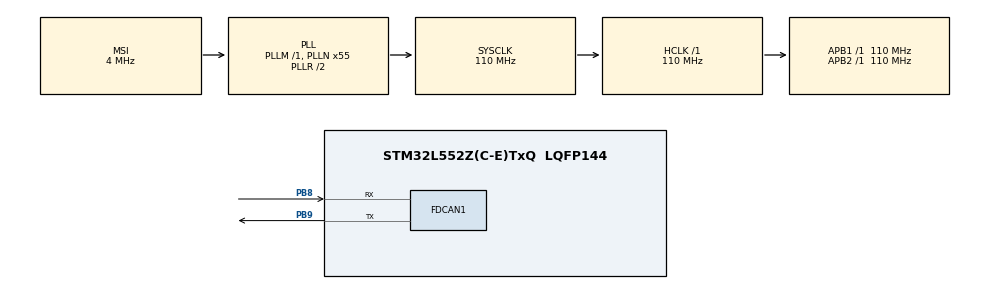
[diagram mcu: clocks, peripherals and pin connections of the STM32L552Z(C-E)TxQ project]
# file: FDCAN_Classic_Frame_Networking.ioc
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FDCAN1.AutoRetransmission=ENABLE
FDCAN1.CalculateBaudRateNominal=1374999
FDCAN1.CalculateTimeBitNominal=727
FDCAN1.CalculateTimeQuantumNominal=9.090909090909092
FDCAN1.ClockDivider=FDCAN_CLOCK_DIV1
FDCAN1.DataPrescaler=1
FDCAN1.DataSyncJumpWidth=4
FDCAN1.DataTimeSeg1=5
FDCAN1.DataTimeSeg2=4
FDCAN1.ExtFiltersNbr=0
FDCAN1.FrameFormat=FDCAN_FRAME_FD_BRS
FDCAN1.Mode=FDCAN_MODE_NORMAL
FDCAN1.NominalPrescaler=1
FDCAN1.NominalSyncJumpWidth=16
FDCAN1.NominalTimeSeg1=63
FDCAN1.NominalTimeSeg2=16
FDCAN1.ProtocolException=DISABLE
FDCAN1.StdFiltersNbr=1
FDCAN1.TransmitPause=ENABLE
FDCAN1.TxFifoQueueMode=FDCAN_TX_FIFO_OPERATION
Mcu.Family=STM32L5
Mcu.Name=STM32L552Z(C-E)TxQ
Mcu.Package=LQFP144
NVIC.FDCAN1_IT0_IRQn=true\:0\:0\:false\:false\:true\:true\:true\:true
NVIC.PriorityGroup=NVIC_PRIORITYGROUP_3
PB8.GPIO_Speed=GPIO_SPEED_FREQ_VERY_HIGH
PB8.Mode=FDCAN_Activate
PB8.Signal=FDCAN1_RX
PB9.GPIO_Speed=GPIO_SPEED_FREQ_VERY_HIGH
PB9.Mode=FDCAN_Activate
PB9.Signal=FDCAN1_TX
ProjectManager.HeapSize=0x200
ProjectManager.StackSize=0x400
ProjectManager.TargetToolchain=EWARM V8.32
RCC.ADCCLockSelection=RCC_ADCCLKSOURCE_SYSCLK
RCC.ADCFreq_Value=110000000
RCC.AHBFreq_Value=110000000
RCC.APB1Freq_Value=110000000
RCC.APB1TimFreq_Value=110000000
RCC.APB2Freq_Value=110000000
RCC.APB2TimFreq_Value=110000000
RCC.CK48CLockSelection=RCC_USBCLKSOURCE_MSI
RCC.CortexFreq_Value=110000000
RCC.DATA_CACHE_ENABLE=0
RCC.HCLKFreq_Value=110000000
RCC.HSE_VALUE=16000000
RCC.HSI48_VALUE=48000000
RCC.HSI_VALUE=16000000
RCC.INSTRUCTION_CACHE_ENABLE=0
RCC.LSE_VALUE=32768
RCC.MSI_VALUE=4000000
RCC.PLLN=55
RCC.SYSCLKFreq_VALUE=110000000
RCC.SYSCLKSource=RCC_SYSCLKSOURCE_PLLCLK
RCC.USBFreq_Value=4000000
RCC.VCOOutputFreq_Value=220000000
VP_ICACHE_VS_ICACHE.Mode=DirectMappedCache
VP_PWR_VS_DBSignals.Mode=DisableDeadBatterySignals
board=custom

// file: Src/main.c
/* USER CODE BEGIN Header */
/**
  ******************************************************************************
  * @file    FDCAN/FDCAN_Classic_Frame_Networking/Src/main.c
  * @author  MCD Application Team
  * @brief   This sample code shows how to configure the FDCAN peripheral to
  *          send and receive Classic CAN frames
  ******************************************************************************
  * @attention
  *
  * Copyright (c) 2019 STMicroelectronics.
  * All rights reserved.
  *
  * This software is licensed under terms that can be found in the LICENSE file
  * in the root directory of this software component.
  * If no LICENSE file comes with this software, it is provided AS-IS.
  *
  ******************************************************************************
  */
/* USER CODE END Header */
#include "main.h"

/* USER CODE BEGIN PD */
#define KEY_PRESSED     GPIO_PIN_SET
#define KEY_NOT_PRESSED GPIO_PIN_RESET

/* USER CODE END PD */

FDCAN_HandleTypeDef hfdcan1;

/* USER CODE BEGIN PV */
uint8_t ubKeyNumber = 0x0;
uint8_t ubKeyNumberValue = 0x0;
FDCAN_RxHeaderTypeDef RxHeader;
uint8_t RxData[8];
FDCAN_TxHeaderTypeDef TxHeader;
uint8_t TxData[8];

/* USER CODE END PV */

void SystemClock_Config(void);
static void MX_GPIO_Init(void);
static void MX_ICACHE_Init(void);
static void MX_FDCAN1_Init(void);
/* USER CODE BEGIN PFP */
static void FDCAN_Config(void);
static void LED_Display(uint8_t LedStatus);

/* USER CODE END PFP */

int main(void)
{
  /* USER CODE BEGIN 1 */

  /* STM32L5xx HAL library initialization:
       - Systick timer is configured by default as source of time base, but user
         can eventually implement his proper time base source (a general purpose
         timer for example or other time source), keeping in mind that Time base
         duration should be kept 1ms since PPP_TIMEOUT_VALUEs are defined and
         handled in milliseconds basis.
       - Set NVIC Group Priority to 3
       - Low Level Initialization
     */
  /* USER CODE END 1 */

  /* MCU Configuration--------------------------------------------------------*/

  /* Reset of all peripherals, Initializes the Flash interface and the Systick. */
  HAL_Init();

  /* USER CODE BEGIN Init */
  BSP_LED_Init(LED4);
  BSP_LED_Init(LED5);
  /* USER CODE END Init */

  /* Configure the system clock */
  SystemClock_Config();

  /* USER CODE BEGIN SysInit */

  /* Configure WKUP push-button in interrupt mode */
  BSP_PB_Init(BUTTON_WAKEUP, BUTTON_MODE_GPIO);

  /* USER CODE END SysInit */

  /* Initialize all configured peripherals */
  MX_GPIO_Init();
  MX_ICACHE_Init();
  MX_FDCAN1_Init();
  /* USER CODE BEGIN 2 */

  /* Configure the FDCAN peripheral */
  FDCAN_Config();
  ubKeyNumberValue = 0x2;

  /* USER CODE END 2 */

  /* Infinite loop */
  /* USER CODE BEGIN WHILE */
  while (1)
  {
    while (BSP_PB_GetState(BUTTON_WAKEUP) == KEY_PRESSED)
    {
      if (ubKeyNumber == ubKeyNumberValue)
      {
        ubKeyNumber = 0x00;
      }
      else
      {
        LED_Display(++ubKeyNumber);

        /* Set the data to be transmitted */
        TxData[0] = ubKeyNumber;
        TxData[1] = 0xAD;

        /* Start the Transmission process */
        if (HAL_FDCAN_AddMessageToTxFifoQ(&hfdcan1, &TxHeader, TxData) != HAL_OK)
        {
          /* Transmission request Error */
          Error_Handler();
        }
        HAL_Delay(10);

        while (BSP_PB_GetState(BUTTON_WAKEUP) != KEY_NOT_PRESSED)
        {
        }
      }
    }
    /* USER CODE END WHILE */

  }
}

void SystemClock_Config(void)
{
  RCC_OscInitTypeDef RCC_OscInitStruct = {0};
  RCC_ClkInitTypeDef RCC_ClkInitStruct = {0};

  /** Configure the main internal regulator output voltage
  */
  if (HAL_PWREx_ControlVoltageScaling(PWR_REGULATOR_VOLTAGE_SCALE0) != HAL_OK)
  {
    Error_Handler();
  }

  /** Initializes the RCC Oscillators according to the specified parameters
  * in the RCC_OscInitTypeDef structure.
  */
  RCC_OscInitStruct.OscillatorType = RCC_OSCILLATORTYPE_MSI;
  RCC_OscInitStruct.MSIState = RCC_MSI_ON;
  RCC_OscInitStruct.MSICalibrationValue = RCC_MSICALIBRATION_DEFAULT;
  RCC_OscInitStruct.MSIClockRange = RCC_MSIRANGE_6;
  RCC_OscInitStruct.PLL.PLLState = RCC_PLL_ON;
  RCC_OscInitStruct.PLL.PLLSource = RCC_PLLSOURCE_MSI;
  RCC_OscInitStruct.PLL.PLLM = 1;
  RCC_OscInitStruct.PLL.PLLN = 55;
  RCC_OscInitStruct.PLL.PLLP = RCC_PLLP_DIV7;
  RCC_OscInitStruct.PLL.PLLQ = RCC_PLLQ_DIV2;
  RCC_OscInitStruct.PLL.PLLR = RCC_PLLR_DIV2;
  if (HAL_RCC_OscConfig(&RCC_OscInitStruct) != HAL_OK)
  {
    Error_Handler();
  }

  /** Initializes the CPU, AHB and APB buses clocks
  */
  RCC_ClkInitStruct.ClockType = RCC_CLOCKTYPE_HCLK|RCC_CLOCKTYPE_SYSCLK
                              |RCC_CLOCKTYPE_PCLK1|RCC_CLOCKTYPE_PCLK2;
  RCC_ClkInitStruct.SYSCLKSource = RCC_SYSCLKSOURCE_PLLCLK;
  RCC_ClkInitStruct.AHBCLKDivider = RCC_SYSCLK_DIV1;
  RCC_ClkInitStruct.APB1CLKDivider = RCC_HCLK_DIV1;
  RCC_ClkInitStruct.APB2CLKDivider = RCC_HCLK_DIV1;

  if (HAL_RCC_ClockConfig(&RCC_ClkInitStruct, FLASH_LATENCY_5) != HAL_OK)
  {
    Error_Handler();
  }
}

static void MX_FDCAN1_Init(void)
{

  hfdcan1.Instance = FDCAN1;
  hfdcan1.Init.ClockDivider = FDCAN_CLOCK_DIV1;
  hfdcan1.Init.FrameFormat = FDCAN_FRAME_FD_BRS;
  hfdcan1.Init.Mode = FDCAN_MODE_NORMAL;
  hfdcan1.Init.AutoRetransmission = ENABLE;
  hfdcan1.Init.TransmitPause = ENABLE;
  hfdcan1.Init.ProtocolException = DISABLE;
  hfdcan1.Init.NominalPrescaler = 1;
  hfdcan1.Init.NominalSyncJumpWidth = 16;
  hfdcan1.Init.NominalTimeSeg1 = 63;
  hfdcan1.Init.NominalTimeSeg2 = 16;
  hfdcan1.Init.DataPrescaler = 1;
  hfdcan1.Init.DataSyncJumpWidth = 4;
  hfdcan1.Init.DataTimeSeg1 = 5;
  hfdcan1.Init.DataTimeSeg2 = 4;
  hfdcan1.Init.StdFiltersNbr = 1;
  hfdcan1.Init.ExtFiltersNbr = 0;
  hfdcan1.Init.TxFifoQueueMode = FDCAN_TX_FIFO_OPERATION;
  if (HAL_FDCAN_Init(&hfdcan1) != HAL_OK)
  {
    Error_Handler();
  }

}

static void MX_ICACHE_Init(void)
{

  /** Enable instruction cache in 1-way (direct mapped cache)
  */
  if (HAL_ICACHE_ConfigAssociativityMode(ICACHE_1WAY) != HAL_OK)
  {
    Error_Handler();
  }
  if (HAL_ICACHE_Enable() != HAL_OK)
  {
    Error_Handler();
  }

}

static void MX_GPIO_Init(void)
{

  /* GPIO Ports Clock Enable */
  __HAL_RCC_GPIOB_CLK_ENABLE();

}

/* USER CODE BEGIN 4 */

/**
  * @brief  Configures the FDCAN.
  * @param  None
  * @retval None
  */
static void FDCAN_Config(void)
{
  FDCAN_FilterTypeDef sFilterConfig;

  /* Configure Rx filter */
  sFilterConfig.IdType = FDCAN_STANDARD_ID;
  sFilterConfig.FilterIndex = 0;
  sFilterConfig.FilterType = FDCAN_FILTER_MASK;
  sFilterConfig.FilterConfig = FDCAN_FILTER_TO_RXFIFO0;
  sFilterConfig.FilterID1 = 0x321;
  sFilterConfig.FilterID2 = 0x7FF;
  if (HAL_FDCAN_ConfigFilter(&hfdcan1, &sFilterConfig) != HAL_OK)
  {
    Error_Handler();
  }

  /* Configure global filter:
     Filter all remote frames with STD and EXT ID
     Reject non matching frames with STD ID and EXT ID */
  if (HAL_FDCAN_ConfigGlobalFilter(&hfdcan1, FDCAN_REJECT, FDCAN_REJECT, FDCAN_FILTER_REMOTE, FDCAN_FILTER_REMOTE) != HAL_OK)
  {
    Error_Handler();
  }

  /* Start the FDCAN module */
  if (HAL_FDCAN_Start(&hfdcan1) != HAL_OK)
  {
    Error_Handler();
  }

  if (HAL_FDCAN_ActivateNotification(&hfdcan1, FDCAN_IT_RX_FIFO0_NEW_MESSAGE, 0) != HAL_OK)
  {
    Error_Handler();
  }

  /* Prepare Tx Header */
  TxHeader.Identifier = 0x321;
  TxHeader.IdType = FDCAN_STANDARD_ID;
  TxHeader.TxFrameType = FDCAN_DATA_FRAME;
  TxHeader.DataLength = FDCAN_DLC_BYTES_2;
  TxHeader.ErrorStateIndicator = FDCAN_ESI_ACTIVE;
  TxHeader.BitRateSwitch = FDCAN_BRS_OFF;
  TxHeader.FDFormat = FDCAN_CLASSIC_CAN;
  TxHeader.TxEventFifoControl = FDCAN_NO_TX_EVENTS;
  TxHeader.MessageMarker = 0;
}

/**
  * @brief  Rx FIFO 0 callback.
  * @param  hfdcan: pointer to an FDCAN_HandleTypeDef structure that contains
  *         the configuration information for the specified FDCAN.
  * @param  RxFifo0ITs: indicates which Rx FIFO 0 interrupts are signalled.
  *         This parameter can be any combination of @arg FDCAN_Rx_Fifo0_Interrupts.
  * @retval None
  */
void HAL_FDCAN_RxFifo0Callback(FDCAN_HandleTypeDef *hfdcan, uint32_t RxFifo0ITs)
{
  if((RxFifo0ITs & FDCAN_IT_RX_FIFO0_NEW_MESSAGE) != RESET)
  {
    /* Retrieve Rx messages from RX FIFO0 */
    if (HAL_FDCAN_GetRxMessage(hfdcan, FDCAN_RX_FIFO0, &RxHeader, RxData) != HAL_OK)
    {
    Error_Handler();
    }

    /* Display LEDx */
    if ((RxHeader.Identifier == 0x321) && (RxHeader.IdType == FDCAN_STANDARD_ID) && (RxHeader.DataLength == FDCAN_DLC_BYTES_2))
    {
      LED_Display(RxData[0]);
      ubKeyNumber = RxData[0];
    }
  }
}

/**
  * @brief  Turns ON/OFF the dedicated LED.
  * @param  LedStatus: LED number from 1 to 2
  * @retval None
  */
void LED_Display(uint8_t LedStatus)
{
  /* Turn OFF all LEDs */
  BSP_LED_Off(LED4);
  BSP_LED_Off(LED5);

  switch(LedStatus)
  {
    case (1):
      /* Turn ON LED4 */
      BSP_LED_On(LED4);
      break;

    case (2):
      /* Turn ON LED5 */
      BSP_LED_On(LED5);
      break;

    default:
      break;
  }
}

/* USER CODE END 4 */

void Error_Handler(void)
{
  /* USER CODE BEGIN Error_Handler_Debug */
  /* User can add his own implementation to report the HAL error return state */
  /* Turn LED4, LED5 on */
  BSP_LED_On(LED4);
  BSP_LED_On(LED5);

  while(1)
  {
  }
  /* USER CODE END Error_Handler_Debug */
}
